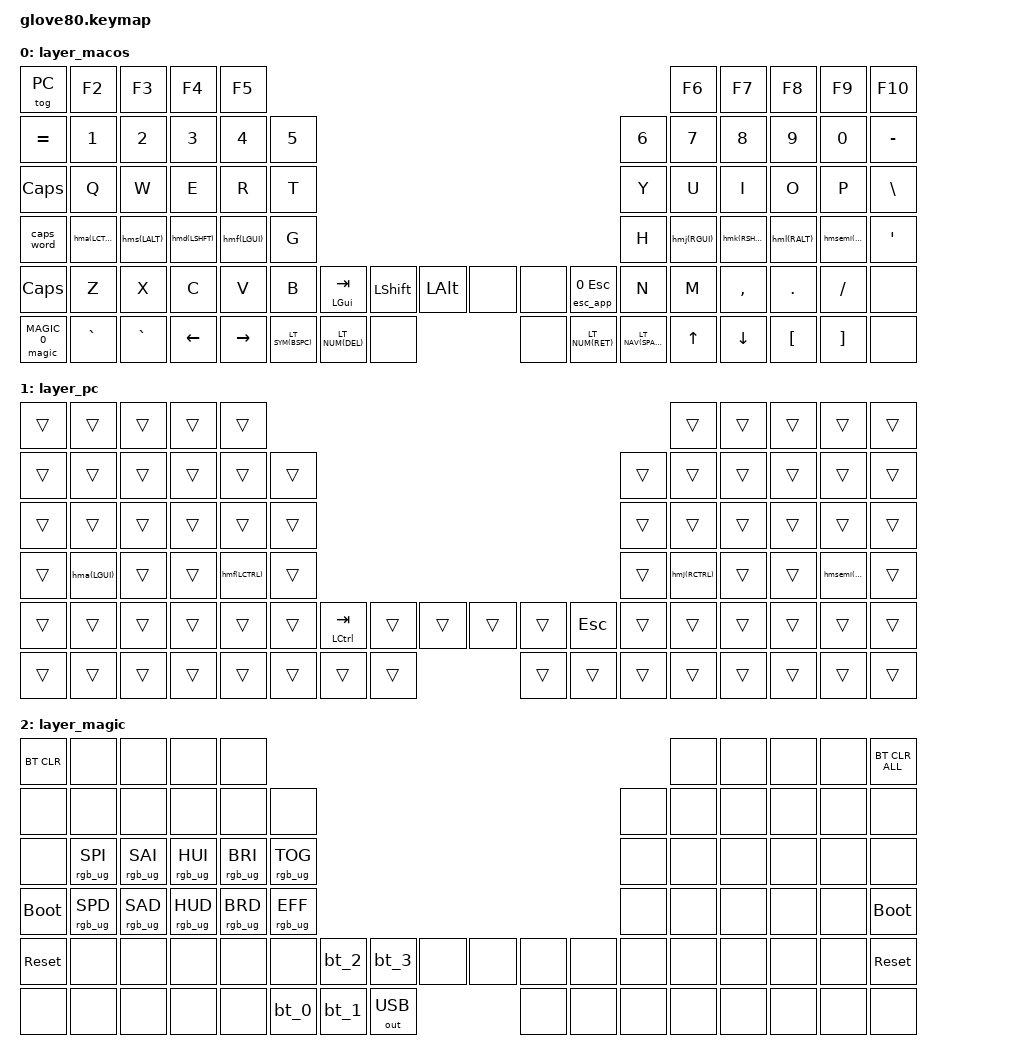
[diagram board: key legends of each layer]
/* Built-in */
#include <behaviors.dtsi>
#include <dt-bindings/zmk/outputs.h>
#include <dt-bindings/zmk/keys.h>
#include <dt-bindings/zmk/bt.h>
#include <dt-bindings/zmk/rgb.h>

/* User-defined */
#include "layers.dtsi"
#include "macros.dtsi"
#include "behavior_overrides.dtsi"
#include "behaviors.dtsi"
#include "bluetooth.dtsi"
#include "positions.dtsi"

/*
Function keys: F1-F10 (or higher)
Navigation:
Arrows
LA(l/r): move word
LG(l/r): move start/end line
LA(u/d): move paragraph
page up/down
HOME/END
shift + arrows = select ...
spotlight
app switcher (cmd-tab, needs arrows and tab in new layer)
next/prev window
move window
maximize window
minimize window
Get rid of caps once hammerspoon becomes redundant
Note that some things are best implemented as combos!!!
bind pc-specific layers to the thumb clusters on the pc layer
*/

#define ______ &trans

/ {
    keymap {
        compatible = "zmk,keymap";

        layer_macos {
            bindings = <
&tog PC               &kp F2       &kp F3      &kp F4       &kp F5                                                                                               &kp F6      &kp F7       &kp F8      &kp F9          &kp F10
&kp EQUAL             &kp N1       &kp N2      &kp N3       &kp N4      &kp N5                                                                           &kp N6  &kp N7      &kp N8       &kp N9      &kp N0          &kp MINUS
&kp CAPS              &kp Q        &kp W       &kp E        &kp R       &kp T                                                                            &kp Y   &kp U       &kp I        &kp O       &kp P           &kp BSLH
&caps_word            &hma(LCTRL)  &hms(LALT)  &hmd(LSHFT)  &hmf(LGUI)  &kp G                                                                            &kp H   &hmj(RGUI)  &hmk(RSHFT)  &hml(RALT)  &hmsemi(RCTRL)  &kp SQT
&kp CAPS              &kp Z        &kp X       &kp C        &kp V       &kp B   &mt LGUI TAB  &kp LSHFT    &kp LALT  &none  &none        &esc_app 0 ESC  &kp N   &kp M       &kp COMMA    &kp DOT     &kp FSLH        &none
&magic MAGIC 0        &kp GRAVE    &kp GRAVE   &kp LEFT     &kp RIGHT           LT_SYM(BSPC)  LT_NUM(DEL)      &none     &none  LT_NUM(RET)  LT_NAV(SPACE)           &kp UP      &kp DOWN     &kp LBKT    &kp RBKT        &none
            >;
        };

        layer_pc {
            bindings = <
______  ______      ______  ______  ______                                                                               ______       ______  ______  ______         ______
______  ______      ______  ______  ______       ______                                                          ______  ______       ______  ______  ______         ______
______  ______      ______  ______  ______       ______                                                          ______  ______       ______  ______  ______         ______
______  &hma(LGUI)  ______  ______  &hmf(LCTRL)  ______                                                          ______  &hmj(RCTRL)  ______  ______  &hmsemi(RGUI)  ______
______  ______      ______  ______  ______       ______  &mt LCTRL TAB  ______  ______  ______  ______  &kp ESC  ______  ______       ______  ______  ______         ______
______  ______      ______  ______  ______               ______         ______  ______  ______  ______  ______           ______       ______  ______  ______         ______
            >;
        };

        layer_magic {
            bindings = <
&bt BT_CLR   &none            &none            &none            &none                                                                                     &none  &none  &none  &none  &bt BT_CLR_ALL
&none        &none            &none            &none            &none            &none                                                             &none  &none  &none  &none  &none  &none
&none        &rgb_ug RGB_SPI  &rgb_ug RGB_SAI  &rgb_ug RGB_HUI  &rgb_ug RGB_BRI  &rgb_ug RGB_TOG                                                   &none  &none  &none  &none  &none  &none
&bootloader  &rgb_ug RGB_SPD  &rgb_ug RGB_SAD  &rgb_ug RGB_HUD  &rgb_ug RGB_BRD  &rgb_ug RGB_EFF                                                   &none  &none  &none  &none  &none  &bootloader
&sys_reset   &none            &none            &none            &none            &none            &bt_2  &bt_3  &none         &none  &none  &none  &none  &none  &none  &none  &none  &sys_reset
&none        &none            &none            &none            &none                             &bt_0  &bt_1  &out OUT_USB  &none  &none  &none         &none  &none  &none  &none  &none
            >;
        };

    };
};
